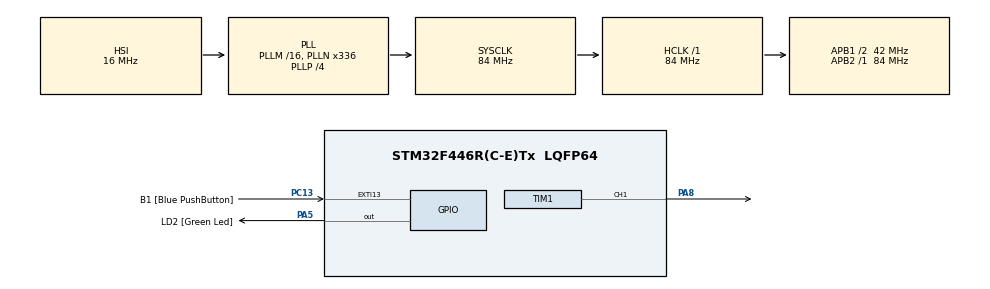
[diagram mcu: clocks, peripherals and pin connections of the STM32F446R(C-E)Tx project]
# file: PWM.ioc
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Mcu.Family=STM32F4
Mcu.Name=STM32F446R(C-E)Tx
Mcu.Package=LQFP64
NVIC.EXTI15_10_IRQn=true\:0\:0\:false\:false\:true\:true\:true\:true
NVIC.PriorityGroup=NVIC_PRIORITYGROUP_0
NVIC.TIM1_CC_IRQn=true\:0\:0\:false\:false\:true\:true\:true\:true
PA2.GPIO_Label=USART_TX
PA2.Signal=USART2_TX
PA3.GPIO_Label=USART_RX
PA3.Signal=USART2_RX
PA5.GPIO_Label=LD2 [Green Led]
PA5.Signal=GPIO_Output
PA8.Signal=S_TIM1_CH1
PC13.GPIO_Label=B1 [Blue PushButton]
PC13.GPIO_ModeDefaultEXTI=GPIO_MODE_IT_FALLING
PC13.Signal=GPXTI13
ProjectManager.HeapSize=0x200
ProjectManager.StackSize=0x400
ProjectManager.TargetToolchain=STM32CubeIDE
RCC.AHBFreq_Value=84000000
RCC.APB1CLKDivider=RCC_HCLK_DIV2
RCC.APB1Freq_Value=42000000
RCC.APB1TimFreq_Value=84000000
RCC.APB2Freq_Value=84000000
RCC.APB2TimFreq_Value=84000000
RCC.CortexFreq_Value=84000000
RCC.FLatency-AdvancedSettings=FLASH_LATENCY_2
RCC.HCLKFreq_Value=84000000
RCC.HSE_VALUE=8000000
RCC.HSI_VALUE=16000000
RCC.LSE_VALUE=32768
RCC.PLLN=336
RCC.PLLP=RCC_PLLP_DIV4
RCC.SYSCLKFreq_VALUE=84000000
RCC.SYSCLKSource=RCC_SYSCLKSOURCE_PLLCLK
RCC.USBFreq_Value=168000000
RCC.VCOOutputFreq_Value=336000000
SH.S_TIM1_CH1.0=TIM1_CH1,PWM Generation1 CH1
TIM1.Channel-PWM\ Generation1\ CH1=TIM_CHANNEL_1
TIM1.Period=1000
TIM1.Pulse-PWM\ Generation1\ CH1=500
VP_TIM1_VS_ClockSourceINT.Mode=Internal
board=NUCLEO-F446RE

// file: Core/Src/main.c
/* USER CODE BEGIN Header */
/**
  ******************************************************************************
  * @file           : main.c
  * @brief          : Main program body
  ******************************************************************************
  * @attention
  *
  * Copyright (c) 2022 STMicroelectronics.
  * All rights reserved.
  *
  * This software is licensed under terms that can be found in the LICENSE file
  * in the root directory of this software component.
  * If no LICENSE file comes with this software, it is provided AS-IS.
  *
  ******************************************************************************
  */
/* USER CODE END Header */
#include "main.h"

TIM_HandleTypeDef htim1;

/* USER CODE BEGIN PV */
uint8_t duty_cycle;
/* USER CODE END PV */

void SystemClock_Config(void);
static void MX_GPIO_Init(void);
static void MX_TIM1_Init(void);

int main(void)
{

  /* MCU Configuration--------------------------------------------------------*/

  /* Reset of all peripherals, Initializes the Flash interface and the Systick. */
  HAL_Init();

  /* Configure the system clock */
  SystemClock_Config();

  /* Initialize all configured peripherals */
  MX_GPIO_Init();
  MX_TIM1_Init();
  /* USER CODE BEGIN 2 */
  htim1.Instance->CCR1 = duty_cycle;
  HAL_TIM_PWM_Start_IT(&htim1, TIM_CHANNEL_1);
  /* USER CODE END 2 */

  /* Infinite loop */
  while (1)
  {

  }
}

void SystemClock_Config(void)
{
  RCC_OscInitTypeDef RCC_OscInitStruct = {0};
  RCC_ClkInitTypeDef RCC_ClkInitStruct = {0};

  /** Configure the main internal regulator output voltage
  */
  __HAL_RCC_PWR_CLK_ENABLE();
  __HAL_PWR_VOLTAGESCALING_CONFIG(PWR_REGULATOR_VOLTAGE_SCALE3);

  /** Initializes the RCC Oscillators according to the specified parameters
  * in the RCC_OscInitTypeDef structure.
  */
  RCC_OscInitStruct.OscillatorType = RCC_OSCILLATORTYPE_HSI;
  RCC_OscInitStruct.HSIState = RCC_HSI_ON;
  RCC_OscInitStruct.HSICalibrationValue = RCC_HSICALIBRATION_DEFAULT;
  RCC_OscInitStruct.PLL.PLLState = RCC_PLL_ON;
  RCC_OscInitStruct.PLL.PLLSource = RCC_PLLSOURCE_HSI;
  RCC_OscInitStruct.PLL.PLLM = 16;
  RCC_OscInitStruct.PLL.PLLN = 336;
  RCC_OscInitStruct.PLL.PLLP = RCC_PLLP_DIV4;
  RCC_OscInitStruct.PLL.PLLQ = 2;
  RCC_OscInitStruct.PLL.PLLR = 2;
  if (HAL_RCC_OscConfig(&RCC_OscInitStruct) != HAL_OK)
  {
    Error_Handler();
  }

  /** Initializes the CPU, AHB and APB buses clocks
  */
  RCC_ClkInitStruct.ClockType = RCC_CLOCKTYPE_HCLK|RCC_CLOCKTYPE_SYSCLK
                              |RCC_CLOCKTYPE_PCLK1|RCC_CLOCKTYPE_PCLK2;
  RCC_ClkInitStruct.SYSCLKSource = RCC_SYSCLKSOURCE_PLLCLK;
  RCC_ClkInitStruct.AHBCLKDivider = RCC_SYSCLK_DIV1;
  RCC_ClkInitStruct.APB1CLKDivider = RCC_HCLK_DIV2;
  RCC_ClkInitStruct.APB2CLKDivider = RCC_HCLK_DIV1;

  if (HAL_RCC_ClockConfig(&RCC_ClkInitStruct, FLASH_LATENCY_2) != HAL_OK)
  {
    Error_Handler();
  }
}

static void MX_TIM1_Init(void)
{

  TIM_ClockConfigTypeDef sClockSourceConfig = {0};
  TIM_MasterConfigTypeDef sMasterConfig = {0};
  TIM_OC_InitTypeDef sConfigOC = {0};
  TIM_BreakDeadTimeConfigTypeDef sBreakDeadTimeConfig = {0};

  htim1.Instance = TIM1;
  htim1.Init.Prescaler = 0;
  htim1.Init.CounterMode = TIM_COUNTERMODE_UP;
  htim1.Init.Period = 1000;
  htim1.Init.ClockDivision = TIM_CLOCKDIVISION_DIV1;
  htim1.Init.RepetitionCounter = 0;
  htim1.Init.AutoReloadPreload = TIM_AUTORELOAD_PRELOAD_DISABLE;
  if (HAL_TIM_Base_Init(&htim1) != HAL_OK)
  {
    Error_Handler();
  }
  sClockSourceConfig.ClockSource = TIM_CLOCKSOURCE_INTERNAL;
  if (HAL_TIM_ConfigClockSource(&htim1, &sClockSourceConfig) != HAL_OK)
  {
    Error_Handler();
  }
  if (HAL_TIM_PWM_Init(&htim1) != HAL_OK)
  {
    Error_Handler();
  }
  sMasterConfig.MasterOutputTrigger = TIM_TRGO_RESET;
  sMasterConfig.MasterSlaveMode = TIM_MASTERSLAVEMODE_DISABLE;
  if (HAL_TIMEx_MasterConfigSynchronization(&htim1, &sMasterConfig) != HAL_OK)
  {
    Error_Handler();
  }
  sConfigOC.OCMode = TIM_OCMODE_PWM1;
  sConfigOC.Pulse = 500;
  sConfigOC.OCPolarity = TIM_OCPOLARITY_HIGH;
  sConfigOC.OCNPolarity = TIM_OCNPOLARITY_HIGH;
  sConfigOC.OCFastMode = TIM_OCFAST_DISABLE;
  sConfigOC.OCIdleState = TIM_OCIDLESTATE_RESET;
  sConfigOC.OCNIdleState = TIM_OCNIDLESTATE_RESET;
  if (HAL_TIM_PWM_ConfigChannel(&htim1, &sConfigOC, TIM_CHANNEL_1) != HAL_OK)
  {
    Error_Handler();
  }
  sBreakDeadTimeConfig.OffStateRunMode = TIM_OSSR_DISABLE;
  sBreakDeadTimeConfig.OffStateIDLEMode = TIM_OSSI_DISABLE;
  sBreakDeadTimeConfig.LockLevel = TIM_LOCKLEVEL_OFF;
  sBreakDeadTimeConfig.DeadTime = 0;
  sBreakDeadTimeConfig.BreakState = TIM_BREAK_DISABLE;
  sBreakDeadTimeConfig.BreakPolarity = TIM_BREAKPOLARITY_HIGH;
  sBreakDeadTimeConfig.AutomaticOutput = TIM_AUTOMATICOUTPUT_DISABLE;
  if (HAL_TIMEx_ConfigBreakDeadTime(&htim1, &sBreakDeadTimeConfig) != HAL_OK)
  {
    Error_Handler();
  }
  HAL_TIM_MspPostInit(&htim1);

}

static void MX_GPIO_Init(void)
{
  GPIO_InitTypeDef GPIO_InitStruct = {0};

  /* GPIO Ports Clock Enable */
  __HAL_RCC_GPIOC_CLK_ENABLE();
  __HAL_RCC_GPIOA_CLK_ENABLE();

  /*Configure GPIO pin Output Level */
  HAL_GPIO_WritePin(LD2_GPIO_Port, LD2_Pin, GPIO_PIN_RESET);

  /*Configure GPIO pin : B1_Pin */
  GPIO_InitStruct.Pin = B1_Pin;
  GPIO_InitStruct.Mode = GPIO_MODE_IT_FALLING;
  GPIO_InitStruct.Pull = GPIO_NOPULL;
  HAL_GPIO_Init(B1_GPIO_Port, &GPIO_InitStruct);

  /*Configure GPIO pins : USART_TX_Pin USART_RX_Pin */
  GPIO_InitStruct.Pin = USART_TX_Pin|USART_RX_Pin;
  GPIO_InitStruct.Mode = GPIO_MODE_AF_PP;
  GPIO_InitStruct.Pull = GPIO_NOPULL;
  GPIO_InitStruct.Speed = GPIO_SPEED_FREQ_VERY_HIGH;
  GPIO_InitStruct.Alternate = GPIO_AF7_USART2;
  HAL_GPIO_Init(GPIOA, &GPIO_InitStruct);

  /*Configure GPIO pin : LD2_Pin */
  GPIO_InitStruct.Pin = LD2_Pin;
  GPIO_InitStruct.Mode = GPIO_MODE_OUTPUT_PP;
  GPIO_InitStruct.Pull = GPIO_NOPULL;
  GPIO_InitStruct.Speed = GPIO_SPEED_FREQ_LOW;
  HAL_GPIO_Init(LD2_GPIO_Port, &GPIO_InitStruct);

  /* EXTI interrupt init*/
  HAL_NVIC_SetPriority(EXTI15_10_IRQn, 0, 0);
  HAL_NVIC_EnableIRQ(EXTI15_10_IRQn);

}

/* USER CODE BEGIN 4 */
void HAL_GPIO_EXTI_Callback(uint16_t GPIO_Pin)
{
  duty_cycle+=10  ;
  if(duty_cycle > 100) duty_cycle = 0 ;
  htim1.Instance->CCR1 = duty_cycle/100.0 * htim1.Instance->ARR ;
}
/* USER CODE END 4 */

void Error_Handler(void)
{
  __disable_irq();
  while (1)
  {
  }
}
